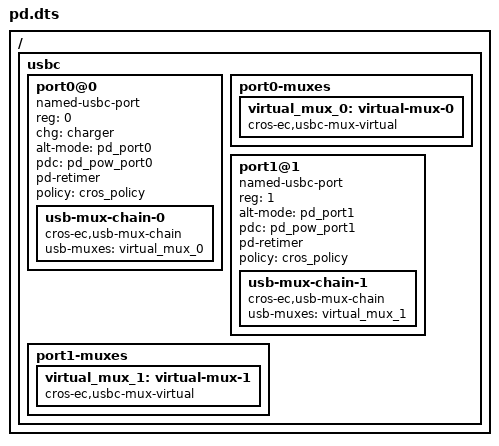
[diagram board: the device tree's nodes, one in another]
/* Copyright 2023 The ChromiumOS Authors
 * Use of this source code is governed by a BSD-style license that can be
 * found in the LICENSE file.
 */

#include <usbc-policy.dtsi>

/ {
	usbc {
		#address-cells = <1>;
		#size-cells = <0>;

		port0@0 {
			compatible = "named-usbc-port";
			reg = <0>;
			chg = <&charger>;
			alt-mode = <&pd_port0>;
			pdc = <&pd_pow_port0>;
			pd-retimer;
			usb-mux-chain-0 {
				compatible = "cros-ec,usb-mux-chain";
				usb-muxes = <&virtual_mux_0>;
			};
			policy = <&cros_policy>;
		};
		port0-muxes {
			virtual_mux_0: virtual-mux-0 {
				compatible = "cros-ec,usbc-mux-virtual";
			};
		};
		port1@1 {
			compatible = "named-usbc-port";
			reg = <1>;
			alt-mode = <&pd_port1>;
			pdc = <&pd_pow_port1>;
			pd-retimer;
			usb-mux-chain-1 {
				compatible = "cros-ec,usb-mux-chain";
				usb-muxes = <&virtual_mux_1>;
			};
			policy = <&cros_policy>;
		};
		port1-muxes {
			virtual_mux_1: virtual-mux-1 {
				compatible = "cros-ec,usbc-mux-virtual";
			};
		};
	};
};
